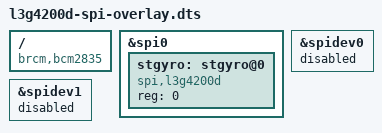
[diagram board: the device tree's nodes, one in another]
// l3g4200d gyro dtob
/dts-v1/;
/plugin/;

/ {
	compatible = "brcm,bcm2835";

	fragment@0 {
		target = <&spi0>;
		__overlay__ {
			status = "okay";
		};
	};

	fragment@1 {
		target = <&spidev0>;
		__overlay__ {
			status = "disabled";
		};
	};

	fragment@2 {
		target = <&spidev1>;
		__overlay__ {
			status = "disabled";
		};
	};

	fragment@3 {
		target = <&spi0>;
		__overlay__ {
        #address-cells = <1>;
        #size-cells = <0>;
			status = "okay";

        	stgyro: stgyro@0 {
				compatible = "spi,l3g4200d";
				reg = <0>;
				status = "okay";
			};
		};
   };
};
